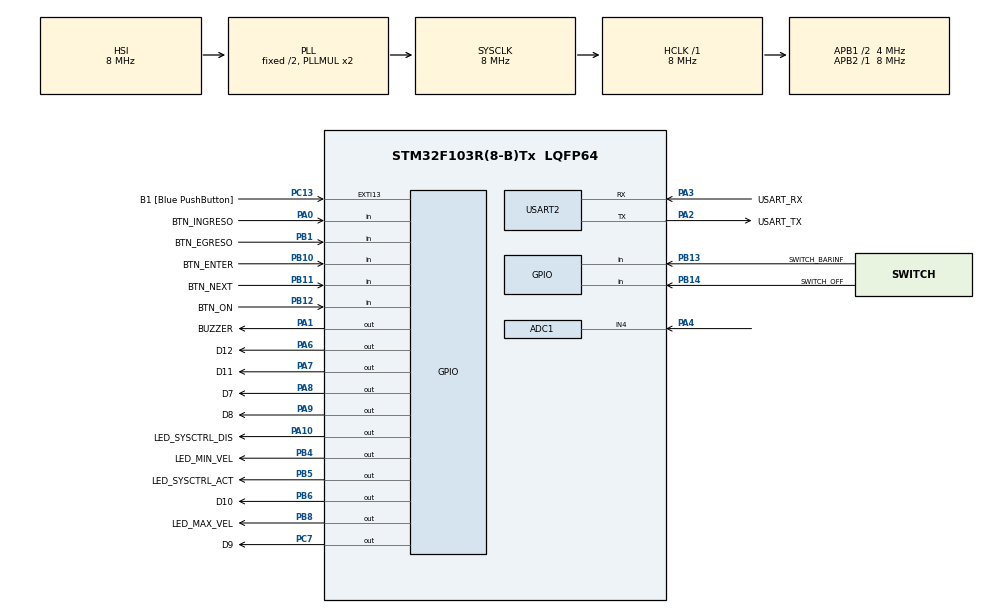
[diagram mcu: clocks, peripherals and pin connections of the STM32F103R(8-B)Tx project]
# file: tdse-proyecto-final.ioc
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ADC1.Channel-0\#ChannelRegularConversion=ADC_CHANNEL_4
ADC1.Channel-1\#ChannelRegularConversion=ADC_CHANNEL_TEMPSENSOR
ADC1.ContinuousConvMode=DISABLE
ADC1.DataAlign=ADC_DATAALIGN_RIGHT
ADC1.NbrOfConversion=2
ADC1.NbrOfConversionFlag=1
ADC1.Rank-0\#ChannelRegularConversion=1
ADC1.Rank-1\#ChannelRegularConversion=2
ADC1.SamplingTime-0\#ChannelRegularConversion=ADC_SAMPLETIME_41CYCLES_5
ADC1.SamplingTime-1\#ChannelRegularConversion=ADC_SAMPLETIME_239CYCLES_5
ADC1.master=1
Dma.ADC1.0.Direction=DMA_PERIPH_TO_MEMORY
Dma.ADC1.0.Instance=DMA1_Channel1
Dma.ADC1.0.MemDataAlignment=DMA_MDATAALIGN_HALFWORD
Dma.ADC1.0.MemInc=DMA_MINC_ENABLE
Dma.ADC1.0.Mode=DMA_CIRCULAR
Dma.ADC1.0.PeriphDataAlignment=DMA_PDATAALIGN_HALFWORD
Dma.ADC1.0.PeriphInc=DMA_PINC_DISABLE
Dma.ADC1.0.Priority=DMA_PRIORITY_LOW
Dma.Request0=ADC1
Mcu.Family=STM32F1
Mcu.Name=STM32F103R(8-B)Tx
Mcu.Package=LQFP64
NVIC.ADC1_2_IRQn=true\:1\:0\:true\:false\:true\:true\:true\:true
NVIC.DMA1_Channel1_IRQn=true\:0\:0\:false\:false\:true\:false\:true\:true
NVIC.EXTI15_10_IRQn=true\:0\:0\:false\:false\:true\:true\:true\:true
NVIC.PriorityGroup=NVIC_PRIORITYGROUP_4
PA0-WKUP.GPIO_Label=BTN_INGRESO
PA0-WKUP.GPIO_PuPd=GPIO_PULLUP
PA0-WKUP.Signal=GPIO_Input
PA1.GPIO_Label=BUZZER
PA1.Signal=GPIO_Output
PA10.GPIO_Label=LED_SYSCTRL_DIS
PA10.Signal=GPIO_Output
PA13.GPIO_Label=TMS
PA13.Mode=Serial_Wire
PA13.Signal=SYS_JTMS-SWDIO
PA14.GPIO_Label=TCK
PA14.Mode=Serial_Wire
PA14.Signal=SYS_JTCK-SWCLK
PA2.GPIO_Label=USART_TX
PA2.GPIO_Mode=GPIO_MODE_AF_PP
PA2.GPIO_PuPd=GPIO_NOPULL
PA2.GPIO_Speed=GPIO_SPEED_FREQ_LOW
PA2.Mode=Asynchronous
PA2.Signal=USART2_TX
PA3.GPIO_Label=USART_RX
PA3.GPIO_Mode=GPIO_MODE_AF_PP
PA3.GPIO_PuPd=GPIO_NOPULL
PA3.GPIO_Speed=GPIO_SPEED_FREQ_LOW
PA3.Mode=Asynchronous
PA3.Signal=USART2_RX
PA4.Signal=ADCx_IN4
PA6.GPIO_Label=D12
PA6.Signal=GPIO_Output
PA7.GPIO_Label=D11
PA7.Signal=GPIO_Output
PA8.GPIO_Label=D7
PA8.Signal=GPIO_Output
PA9.GPIO_Label=D8
PA9.Signal=GPIO_Output
PB1.GPIO_Label=BTN_EGRESO
PB1.GPIO_PuPd=GPIO_PULLUP
PB1.Signal=GPIO_Input
PB10.GPIO_Label=BTN_ENTER
PB10.GPIO_PuPd=GPIO_PULLUP
PB10.Signal=GPIO_Input
PB11.GPIO_Label=BTN_NEXT
PB11.GPIO_PuPd=GPIO_PULLUP
PB11.Signal=GPIO_Input
PB12.GPIO_Label=BTN_ON
PB12.GPIO_PuPd=GPIO_PULLUP
PB12.Signal=GPIO_Input
PB13.GPIO_Label=SWITCH_BARINF
PB13.GPIO_PuPd=GPIO_PULLUP
PB13.Signal=GPIO_Input
PB14.GPIO_Label=SWITCH_OFF
PB14.GPIO_PuPd=GPIO_PULLUP
PB14.Signal=GPIO_Input
PB3.GPIO_Label=SWO
PB3.Signal=SYS_JTDO-TRACESWO
PB4.GPIO_Label=LED_MIN_VEL
PB4.Signal=GPIO_Output
PB5.GPIO_Label=LED_SYSCTRL_ACT
PB5.Signal=GPIO_Output
PB6.GPIO_Label=D10
PB6.Signal=GPIO_Output
PB8.GPIO_Label=LED_MAX_VEL
PB8.Signal=GPIO_Output
PC13-TAMPER-RTC.GPIO_Label=B1 [Blue PushButton]
PC13-TAMPER-RTC.GPIO_PuPd=GPIO_NOPULL
PC13-TAMPER-RTC.Signal=GPXTI13
PC14-OSC32_IN.Mode=LSE-External-Oscillator
PC14-OSC32_IN.Signal=RCC_OSC32_IN
PC15-OSC32_OUT.Mode=LSE-External-Oscillator
PC15-OSC32_OUT.Signal=RCC_OSC32_OUT
PC7.GPIO_Label=D9
PC7.Signal=GPIO_Output
PD0-OSC_IN.Mode=HSE-External-Clock-Source
PD0-OSC_IN.Signal=RCC_OSC_IN
PD1-OSC_OUT.Mode=HSE-External-Clock-Source
PD1-OSC_OUT.Signal=RCC_OSC_OUT
ProjectManager.HeapSize=0x200
ProjectManager.StackSize=0x400
ProjectManager.TargetToolchain=STM32CubeIDE
RCC.AHBFreq_Value=8000000
RCC.APB1CLKDivider=RCC_HCLK_DIV2
RCC.APB1Freq_Value=4000000
RCC.APB1TimFreq_Value=8000000
RCC.APB2Freq_Value=8000000
RCC.APB2TimFreq_Value=8000000
RCC.HCLKFreq_Value=8000000
RCC.RTCClockSelection=RCC_RTCCLKSOURCE_LSE
RCC.SYSCLKFreq_VALUE=8000000
RCC.SYSCLKSource=RCC_SYSCLKSOURCE_PLLCLK
RCC.USBFreq_Value=8000000
SH.ADCx_IN4.0=ADC1_IN4,IN4
USART2.VirtualMode=VM_ASYNC
VP_ADC1_TempSens_Input.Mode=IN-TempSens
board=NUCLEO-F103RB

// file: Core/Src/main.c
/* USER CODE BEGIN Header */
/**
  ******************************************************************************
  * @file           : main.c
  * @brief          : Main program body
  ******************************************************************************
  * @attention
  *
  * Copyright (c) 2025 STMicroelectronics.
  * All rights reserved.
  *
  * This software is licensed under terms that can be found in the LICENSE file
  * in the root directory of this software component.
  * If no LICENSE file comes with this software, it is provided AS-IS.
  *
  ******************************************************************************
  */
/* USER CODE END Header */
#include "main.h"

/* USER CODE BEGIN Includes */
#include "app.h"
#include "board.h"
#include "dwt.h"
#include "display.h"
#include <stdio.h>
#include <stdint.h>

/* USER CODE END Includes */

ADC_HandleTypeDef hadc1;
DMA_HandleTypeDef hdma_adc1;

UART_HandleTypeDef huart2;

void SystemClock_Config(void);
static void MX_GPIO_Init(void);
static void MX_DMA_Init(void);
static void MX_USART2_UART_Init(void);
static void MX_ADC1_Init(void);

/* USER CODE BEGIN 0 */
extern void initialise_monitor_handles(void);
/* USER CODE END 0 */

int main(void)
{

  /* USER CODE BEGIN 1 */
	initialise_monitor_handles();
  /* USER CODE END 1 */

  /* MCU Configuration--------------------------------------------------------*/

  /* Reset of all peripherals, Initializes the Flash interface and the Systick. */
  HAL_Init();

  /* Configure the system clock */
  SystemClock_Config();

  /* Initialize all configured peripherals */
  MX_GPIO_Init();
  MX_DMA_Init();
  MX_USART2_UART_Init();
  MX_ADC1_Init();
  /* USER CODE BEGIN 2 */
  app_init();

  /* USER CODE END 2 */

  /* Infinite loop */
  while (1)
  {
	  app_update();
  }
}

void SystemClock_Config(void)
{
  RCC_OscInitTypeDef RCC_OscInitStruct = {0};
  RCC_ClkInitTypeDef RCC_ClkInitStruct = {0};
  RCC_PeriphCLKInitTypeDef PeriphClkInit = {0};

  /** Initializes the RCC Oscillators according to the specified parameters
  * in the RCC_OscInitTypeDef structure.
  */
  RCC_OscInitStruct.OscillatorType = RCC_OSCILLATORTYPE_HSI;
  RCC_OscInitStruct.HSIState = RCC_HSI_ON;
  RCC_OscInitStruct.HSICalibrationValue = RCC_HSICALIBRATION_DEFAULT;
  RCC_OscInitStruct.PLL.PLLState = RCC_PLL_ON;
  RCC_OscInitStruct.PLL.PLLSource = RCC_PLLSOURCE_HSI_DIV2;
  RCC_OscInitStruct.PLL.PLLMUL = RCC_PLL_MUL2;
  if (HAL_RCC_OscConfig(&RCC_OscInitStruct) != HAL_OK)
  {
    Error_Handler();
  }

  /** Initializes the CPU, AHB and APB buses clocks
  */
  RCC_ClkInitStruct.ClockType = RCC_CLOCKTYPE_HCLK|RCC_CLOCKTYPE_SYSCLK
                              |RCC_CLOCKTYPE_PCLK1|RCC_CLOCKTYPE_PCLK2;
  RCC_ClkInitStruct.SYSCLKSource = RCC_SYSCLKSOURCE_PLLCLK;
  RCC_ClkInitStruct.AHBCLKDivider = RCC_SYSCLK_DIV1;
  RCC_ClkInitStruct.APB1CLKDivider = RCC_HCLK_DIV2;
  RCC_ClkInitStruct.APB2CLKDivider = RCC_HCLK_DIV1;

  if (HAL_RCC_ClockConfig(&RCC_ClkInitStruct, FLASH_LATENCY_0) != HAL_OK)
  {
    Error_Handler();
  }
  PeriphClkInit.PeriphClockSelection = RCC_PERIPHCLK_ADC;
  PeriphClkInit.AdcClockSelection = RCC_ADCPCLK2_DIV2;
  if (HAL_RCCEx_PeriphCLKConfig(&PeriphClkInit) != HAL_OK)
  {
    Error_Handler();
  }
}

static void MX_ADC1_Init(void)
{

  ADC_ChannelConfTypeDef sConfig = {0};

  /** Common config
  */
  hadc1.Instance = ADC1;
  hadc1.Init.ScanConvMode = ADC_SCAN_ENABLE;
  hadc1.Init.ContinuousConvMode = DISABLE;
  hadc1.Init.DiscontinuousConvMode = DISABLE;
  hadc1.Init.ExternalTrigConv = ADC_SOFTWARE_START;
  hadc1.Init.DataAlign = ADC_DATAALIGN_RIGHT;
  hadc1.Init.NbrOfConversion = 2;
  if (HAL_ADC_Init(&hadc1) != HAL_OK)
  {
    Error_Handler();
  }

  /** Configure Regular Channel
  */
  sConfig.Channel = ADC_CHANNEL_4;
  sConfig.Rank = ADC_REGULAR_RANK_1;
  sConfig.SamplingTime = ADC_SAMPLETIME_41CYCLES_5;
  if (HAL_ADC_ConfigChannel(&hadc1, &sConfig) != HAL_OK)
  {
    Error_Handler();
  }

  /** Configure Regular Channel
  */
  sConfig.Channel = ADC_CHANNEL_TEMPSENSOR;
  sConfig.Rank = ADC_REGULAR_RANK_2;
  sConfig.SamplingTime = ADC_SAMPLETIME_239CYCLES_5;
  if (HAL_ADC_ConfigChannel(&hadc1, &sConfig) != HAL_OK)
  {
    Error_Handler();
  }

}

static void MX_USART2_UART_Init(void)
{

  huart2.Instance = USART2;
  huart2.Init.BaudRate = 115200;
  huart2.Init.WordLength = UART_WORDLENGTH_8B;
  huart2.Init.StopBits = UART_STOPBITS_1;
  huart2.Init.Parity = UART_PARITY_NONE;
  huart2.Init.Mode = UART_MODE_TX_RX;
  huart2.Init.HwFlowCtl = UART_HWCONTROL_NONE;
  huart2.Init.OverSampling = UART_OVERSAMPLING_16;
  if (HAL_UART_Init(&huart2) != HAL_OK)
  {
    Error_Handler();
  }

}

static void MX_DMA_Init(void)
{

  /* DMA controller clock enable */
  __HAL_RCC_DMA1_CLK_ENABLE();

  /* DMA interrupt init */
  /* DMA1_Channel1_IRQn interrupt configuration */
  HAL_NVIC_SetPriority(DMA1_Channel1_IRQn, 0, 0);
  HAL_NVIC_EnableIRQ(DMA1_Channel1_IRQn);

}

static void MX_GPIO_Init(void)
{
  GPIO_InitTypeDef GPIO_InitStruct = {0};

  /* GPIO Ports Clock Enable */
  __HAL_RCC_GPIOC_CLK_ENABLE();
  __HAL_RCC_GPIOD_CLK_ENABLE();
  __HAL_RCC_GPIOA_CLK_ENABLE();
  __HAL_RCC_GPIOB_CLK_ENABLE();

  /*Configure GPIO pin Output Level */
  HAL_GPIO_WritePin(GPIOA, BUZZER_Pin|D12_Pin|D11_Pin|D7_Pin
                          |D8_Pin|LED_SYSCTRL_DIS_Pin, GPIO_PIN_RESET);

  /*Configure GPIO pin Output Level */
  HAL_GPIO_WritePin(D9_GPIO_Port, D9_Pin, GPIO_PIN_RESET);

  /*Configure GPIO pin Output Level */
  HAL_GPIO_WritePin(GPIOB, LED_MIN_VEL_Pin|LED_SYSCTRL_ACT_Pin|D10_Pin|LED_MAX_VEL_Pin, GPIO_PIN_RESET);

  /*Configure GPIO pin : B1_Pin */
  GPIO_InitStruct.Pin = B1_Pin;
  GPIO_InitStruct.Mode = GPIO_MODE_IT_RISING;
  GPIO_InitStruct.Pull = GPIO_NOPULL;
  HAL_GPIO_Init(B1_GPIO_Port, &GPIO_InitStruct);

  /*Configure GPIO pin : BTN_INGRESO_Pin */
  GPIO_InitStruct.Pin = BTN_INGRESO_Pin;
  GPIO_InitStruct.Mode = GPIO_MODE_INPUT;
  GPIO_InitStruct.Pull = GPIO_PULLUP;
  HAL_GPIO_Init(BTN_INGRESO_GPIO_Port, &GPIO_InitStruct);

  /*Configure GPIO pins : BUZZER_Pin D12_Pin D11_Pin D7_Pin
                           D8_Pin LED_SYSCTRL_DIS_Pin */
  GPIO_InitStruct.Pin = BUZZER_Pin|D12_Pin|D11_Pin|D7_Pin
                          |D8_Pin|LED_SYSCTRL_DIS_Pin;
  GPIO_InitStruct.Mode = GPIO_MODE_OUTPUT_PP;
  GPIO_InitStruct.Pull = GPIO_NOPULL;
  GPIO_InitStruct.Speed = GPIO_SPEED_FREQ_LOW;
  HAL_GPIO_Init(GPIOA, &GPIO_InitStruct);

  /*Configure GPIO pins : BTN_EGRESO_Pin BTN_ENTER_Pin BTN_NEXT_Pin BTN_ON_Pin
                           SWITCH_BARINF_Pin SWITCH_OFF_Pin */
  GPIO_InitStruct.Pin = BTN_EGRESO_Pin|BTN_ENTER_Pin|BTN_NEXT_Pin|BTN_ON_Pin
                          |SWITCH_BARINF_Pin|SWITCH_OFF_Pin;
  GPIO_InitStruct.Mode = GPIO_MODE_INPUT;
  GPIO_InitStruct.Pull = GPIO_PULLUP;
  HAL_GPIO_Init(GPIOB, &GPIO_InitStruct);

  /*Configure GPIO pin : D9_Pin */
  GPIO_InitStruct.Pin = D9_Pin;
  GPIO_InitStruct.Mode = GPIO_MODE_OUTPUT_PP;
  GPIO_InitStruct.Pull = GPIO_NOPULL;
  GPIO_InitStruct.Speed = GPIO_SPEED_FREQ_LOW;
  HAL_GPIO_Init(D9_GPIO_Port, &GPIO_InitStruct);

  /*Configure GPIO pins : LED_MIN_VEL_Pin LED_SYSCTRL_ACT_Pin D10_Pin LED_MAX_VEL_Pin */
  GPIO_InitStruct.Pin = LED_MIN_VEL_Pin|LED_SYSCTRL_ACT_Pin|D10_Pin|LED_MAX_VEL_Pin;
  GPIO_InitStruct.Mode = GPIO_MODE_OUTPUT_PP;
  GPIO_InitStruct.Pull = GPIO_NOPULL;
  GPIO_InitStruct.Speed = GPIO_SPEED_FREQ_LOW;
  HAL_GPIO_Init(GPIOB, &GPIO_InitStruct);

  /* EXTI interrupt init*/
  HAL_NVIC_SetPriority(EXTI15_10_IRQn, 0, 0);
  HAL_NVIC_EnableIRQ(EXTI15_10_IRQn);

}

void Error_Handler(void)
{
  __disable_irq();
  while (1)
  {
  }
}
